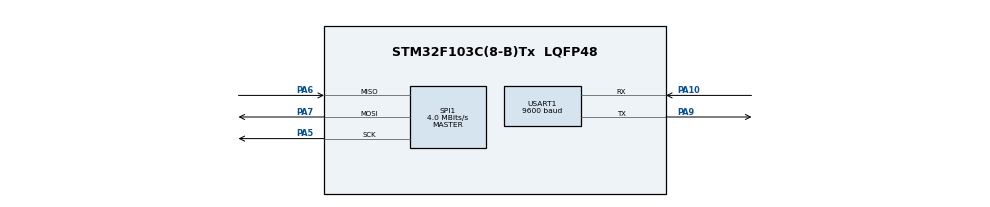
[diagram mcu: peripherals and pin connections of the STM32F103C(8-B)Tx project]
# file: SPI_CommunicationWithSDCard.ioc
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FATFS._MAX_SS=4096
FATFS._USE_LFN=1
Mcu.Family=STM32F1
Mcu.Name=STM32F103C(8-B)Tx
Mcu.Package=LQFP48
NVIC.PriorityGroup=NVIC_PRIORITYGROUP_4
PA10.Mode=Asynchronous
PA10.Signal=USART1_RX
PA13.Mode=Serial_Wire
PA13.Signal=SYS_JTMS-SWDIO
PA14.Mode=Serial_Wire
PA14.Signal=SYS_JTCK-SWCLK
PA5.Mode=Full_Duplex_Master
PA5.Signal=SPI1_SCK
PA6.Mode=Full_Duplex_Master
PA6.Signal=SPI1_MISO
PA7.Mode=Full_Duplex_Master
PA7.Signal=SPI1_MOSI
PA9.Mode=Asynchronous
PA9.Signal=USART1_TX
ProjectManager.HeapSize=0x200
ProjectManager.StackSize=0x400
ProjectManager.TargetToolchain=MDK-ARM V5
RCC.APB1Freq_Value=8000000
RCC.APB2Freq_Value=8000000
SPI1.CalculateBaudRate=4.0 MBits/s
SPI1.Direction=SPI_DIRECTION_2LINES
SPI1.Mode=SPI_MODE_MASTER
SPI1.VirtualType=VM_MASTER
USART1.BaudRate=9600
USART1.VirtualMode=VM_ASYNC
VP_FATFS_VS_Generic.Mode=User_defined
board=custom

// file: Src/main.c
/* USER CODE BEGIN Header */
/**
  ******************************************************************************
  * @file           : main.c
  * @brief          : Main program body
  ******************************************************************************
  * @attention
  *
  * <h2><center>&copy; Copyright (c) 2019 STMicroelectronics.
  * All rights reserved.</center></h2>
  *
  * This software component is licensed by ST under Ultimate Liberty license
  * SLA0044, the "License"; You may not use this file except in compliance with
  * the License. You may obtain a copy of the License at:
  *                             www.st.com/SLA0044
  *
  ******************************************************************************
  */
	/* --COPYRIGHT--,
	 * Copyright (c) 2019, TAPIT Co., Ltd.
	 * https://tapit.vn
	 * ******************** SPI_CommunicationWithSDCard ***********************
	 *  Description: Use the sd library to create files, write files, read files
	 *  Version:    1.0
	 *  Author:     Hang Tran
	 *  Release:    May 27, 2019
	 *  Built with CubeMX Version 5.2.0 and Keil C Version 5.26.2
	 **************************************************************************
	 */
/* USER CODE END Header */

#include "main.h"
#include "fatfs.h"

/* USER CODE BEGIN Includes */
#include "sd.h"

/* USER CODE END Includes */

SPI_HandleTypeDef hspi1;

UART_HandleTypeDef huart1;

/* USER CODE BEGIN PV */
volatile uint16_t Timer1;
extern FATFS SDFatFs; //File system object structure (FATFS)
struct sd_data SD;

/* USER CODE END PV */

void SystemClock_Config(void);
static void MX_GPIO_Init(void);
static void MX_SPI1_Init(void);
static void MX_USART1_UART_Init(void);

int main(void)
{

  /* MCU Configuration--------------------------------------------------------*/

  /* Reset of all peripherals, Initializes the Flash interface and the Systick. */
  HAL_Init();

  /* Configure the system clock */
  SystemClock_Config();

  /* Initialize all configured peripherals */
  MX_GPIO_Init();
  MX_SPI1_Init();
  MX_FATFS_Init();
  MX_USART1_UART_Init();
  /* USER CODE BEGIN 2 */
	SD_Write_File("Hang.txt", "123", 3);
	SD_List_File();

  /* USER CODE END 2 */

  /* Infinite loop */
  while (1)
  {

  }
}

void SystemClock_Config(void)
{
  RCC_OscInitTypeDef RCC_OscInitStruct = {0};
  RCC_ClkInitTypeDef RCC_ClkInitStruct = {0};

  /** Initializes the CPU, AHB and APB busses clocks
  */
  RCC_OscInitStruct.OscillatorType = RCC_OSCILLATORTYPE_HSI;
  RCC_OscInitStruct.HSIState = RCC_HSI_ON;
  RCC_OscInitStruct.HSICalibrationValue = RCC_HSICALIBRATION_DEFAULT;
  RCC_OscInitStruct.PLL.PLLState = RCC_PLL_NONE;
  if (HAL_RCC_OscConfig(&RCC_OscInitStruct) != HAL_OK)
  {
    Error_Handler();
  }
  /** Initializes the CPU, AHB and APB busses clocks
  */
  RCC_ClkInitStruct.ClockType = RCC_CLOCKTYPE_HCLK|RCC_CLOCKTYPE_SYSCLK
                              |RCC_CLOCKTYPE_PCLK1|RCC_CLOCKTYPE_PCLK2;
  RCC_ClkInitStruct.SYSCLKSource = RCC_SYSCLKSOURCE_HSI;
  RCC_ClkInitStruct.AHBCLKDivider = RCC_SYSCLK_DIV1;
  RCC_ClkInitStruct.APB1CLKDivider = RCC_HCLK_DIV1;
  RCC_ClkInitStruct.APB2CLKDivider = RCC_HCLK_DIV1;

  if (HAL_RCC_ClockConfig(&RCC_ClkInitStruct, FLASH_LATENCY_0) != HAL_OK)
  {
    Error_Handler();
  }
}

static void MX_SPI1_Init(void)
{

  /* SPI1 parameter configuration*/
  hspi1.Instance = SPI1;
  hspi1.Init.Mode = SPI_MODE_MASTER;
  hspi1.Init.Direction = SPI_DIRECTION_2LINES;
  hspi1.Init.DataSize = SPI_DATASIZE_8BIT;
  hspi1.Init.CLKPolarity = SPI_POLARITY_LOW;
  hspi1.Init.CLKPhase = SPI_PHASE_1EDGE;
  hspi1.Init.NSS = SPI_NSS_SOFT;
  hspi1.Init.BaudRatePrescaler = SPI_BAUDRATEPRESCALER_2;
  hspi1.Init.FirstBit = SPI_FIRSTBIT_MSB;
  hspi1.Init.TIMode = SPI_TIMODE_DISABLE;
  hspi1.Init.CRCCalculation = SPI_CRCCALCULATION_DISABLE;
  hspi1.Init.CRCPolynomial = 10;
  if (HAL_SPI_Init(&hspi1) != HAL_OK)
  {
    Error_Handler();
  }

}

static void MX_USART1_UART_Init(void)
{

  huart1.Instance = USART1;
  huart1.Init.BaudRate = 9600;
  huart1.Init.WordLength = UART_WORDLENGTH_8B;
  huart1.Init.StopBits = UART_STOPBITS_1;
  huart1.Init.Parity = UART_PARITY_NONE;
  huart1.Init.Mode = UART_MODE_TX_RX;
  huart1.Init.HwFlowCtl = UART_HWCONTROL_NONE;
  huart1.Init.OverSampling = UART_OVERSAMPLING_16;
  if (HAL_UART_Init(&huart1) != HAL_OK)
  {
    Error_Handler();
  }

}

static void MX_GPIO_Init(void)
{

  /* GPIO Ports Clock Enable */
  __HAL_RCC_GPIOA_CLK_ENABLE();

}

void Error_Handler(void)
{
}

/************************ (C) COPYRIGHT STMicroelectronics *****END OF FILE****/
